VERSION ""

NS_ :

BS_:

BU_: Radar

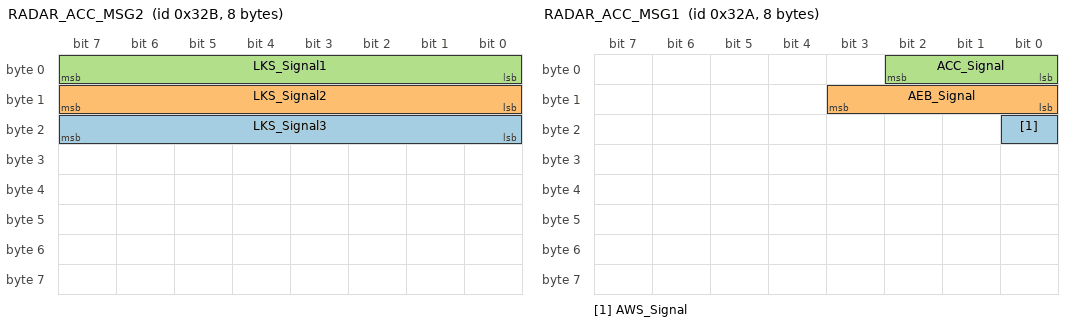
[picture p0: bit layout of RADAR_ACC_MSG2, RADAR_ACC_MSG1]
BO_ 811 RADAR_ACC_MSG2: 8 Radar
 SG_ LKS_Signal3 : 16|8@1+ (1,0) [0|255] "" Vector__XXX
 SG_ LKS_Signal2 : 8|8@1+ (1,0) [0|255] "" Vector__XXX
 SG_ LKS_Signal1 : 0|8@1+ (1,0) [0|255] "" Vector__XXX

BO_ 810 RADAR_ACC_MSG1: 8 Radar
 SG_ AWS_Signal : 16|1@1+ (1,0) [0|1] "" Vector__XXX
 SG_ AEB_Signal : 8|4@1+ (1,0) [0|15] "" Vector__XXX
 SG_ ACC_Signal : 0|3@1+ (1,0) [0|7] "" Vector__XXX

BA_DEF_ BU_  "NodeLayerModule" STRING ;
BA_DEF_ BU_  "ILUSED" ENUM  "Yes","No";
BA_DEF_ SG_  "GenSigStartValue" INT 0 0;
BA_DEF_ BO_  "GenMsgSendType" ENUM  "FixedPeriodic","EventPeriodic","Event";
BA_DEF_ BO_  "GenMsgCycleTime" INT 0 20000;
BA_DEF_DEF_  "NodeLayerModule" "CANoeILNLVector.dll";
BA_DEF_DEF_  "ILUSED" "Yes";
BA_DEF_DEF_  "GenSigStartValue" 0;
BA_DEF_DEF_  "GenMsgSendType" "FixedPeriodic";
BA_DEF_DEF_  "GenMsgCycleTime" 50;
BA_ "GenSigStartValue" SG_ 811 LKS_Signal2 20;
BA_ "GenSigStartValue" SG_ 811 LKS_Signal1 7;
BA_ "GenSigStartValue" SG_ 810 AEB_Signal 10;
BA_ "GenSigStartValue" SG_ 810 ACC_Signal 3;
